# SAM9X60 device description
Architecture: ARM926EJS; Family: SAM9; Series: SAM9X
Registers are 32-bit, read-write, no defined reset value unless marked. A register's access mark holds for its fields unless they carry their own. Offsets are from the block's base; [hi:lo] are bit positions.

## SDRAMC — SDRAM Controller
Instances: SDRAMC 0xFFFFEC00
0x00 SDRAMC_MR — Mode Register
  [2:0] MODE — SDRAMC Command Mode
    0=NORMAL (Normal mode. Any access to the SDRAM is decoded normally. To activate this mode, the command must be followed by a write to the SDRAM.); 1=NOP (The SDRAMC issues a NOP command when the SDRAM device is accessed regardless of the cycle. To activate this mode, the command must be followed by a write to the SDRAM.); 2=ALLBANKS_PRECHARGE (The SDRAMC issues an "All Banks Precharge" command when the SDRAM device is accessed regardless of the cycle. To activate this mode, the command must be followed by a write to the SDRAM.); 3=LOAD_MODEREG (The SDRAMC issues a "Load Mode Register" command when the SDRAM device is accessed regardless of the cycle. To activate this mode, the command must be followed by a write to the SDRAM.); 4=AUTO_REFRESH (The SDRAMC issues an "Autorefresh" Command when the SDRAM device is accessed regardless of the cycle. Previously, an "All Banks Precharge" command must be issued. To activate this mode, the command must be followed by a write to the SDRAM.); 5=EXT_LOAD_MODEREG (The SDRAMC issues an "Extended Load Mode Register" command when the SDRAM device is accessed regardless of the cycle. To activate this mode, the "Extended Load Mode Register" command must be followed by a write to the SDRAM. The write in the SDRAM must be done in the appropriate bank; most low-power SDRAM devices use the bank 1.); 6=DEEP_POWERDOWN (Deep Powerdown mode. Enters Deep Powerdown mode.)
0x04 SDRAMC_TR — Refresh Timer Register
  [11:0] COUNT — SDRAMC Refresh Timer Count
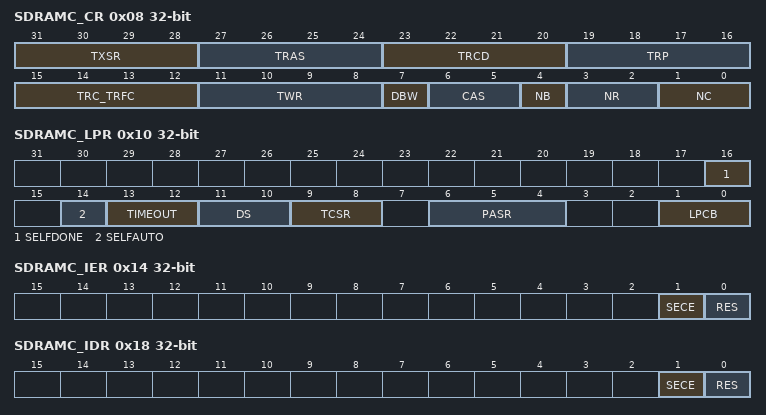
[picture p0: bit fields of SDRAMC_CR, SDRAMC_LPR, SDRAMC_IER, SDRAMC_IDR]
0x08 SDRAMC_CR — Configuration Register
  [31:28] TXSR — Exit Self-Refresh to Active Delay
  [27:24] TRAS — Active to Precharge Delay
  [23:20] TRCD — Row to Column Delay
  [19:16] TRP — Row Precharge Delay
  [15:12] TRC_TRFC — Row Cycle Delay and Row Refresh Cycle
  [11:8] TWR — Write Recovery Delay
  [7] DBW — Data Bus Width
  [6:5] CAS — CAS Latency
    2=LATENCY2 (2-cycle latency); 3=LATENCY3 (3-cycle latency)
  [4] NB — Number of Banks
    0=BANK2 (2 banks); 1=BANK4 (4 banks)
  [3:2] NR — Number of Row Bits
    0=ROW11 (11 bits to define the row number, up to 2048 rows); 1=ROW12 (12 bits to define the row number, up to 4096 rows); 2=ROW13 (13 bits to define the row number, up to 8192 rows)
  [1:0] NC — Number of Column Bits
    0=COL8 (8 bits to define the column number, up to 256 columns); 1=COL9 (9 bits to define the column number, up to 512 columns); 2=COL10 (10 bits to define the column number, up to 1024 columns); 3=COL11 (11 bits to define the column number, up to 2048 columns)
0x0C SDRAMC_HSR — High-Speed Register
  [0] DA — Decode Cycle Enable
0x10 SDRAMC_LPR — Low-Power Register
  [16] SELFDONE — Self-refresh Done (read-only)
  [14] SELFAUTO — Self-refresh Exit Autorefresh
  [13:12] TIMEOUT — Time to Define When Low-power Mode Is Enabled
    0=LP_LAST_XFER (The SDRAMC activates the SDRAM Low-power mode immediately after the end of the last transfer.); 1=LP_LAST_XFER_64 (The SDRAMC activates the SDRAM Low-power mode 64 clock cycles after the end of the last transfer.); 2=LP_LAST_XFER_128 (The SDRAMC activates the SDRAM Low-power mode 128 clock cycles after the end of the last transfer.)
  [11:10] DS — Drive Strength (only for low-power SDRAM)
  [9:8] TCSR — Temperature Compensated Self-Refresh (only for low-power SDRAM)
  [6:4] PASR — Partial Array Self-refresh (only for low-power SDRAM)
  [1:0] LPCB — Low-power Configuration Bits
    0=DISABLED (The low-power feature is inhibited: no Powerdown, Self-refresh or Deep Powerdown command is issued to the SDRAM device.); 1=SELF_REFRESH (The SDRAMC issues a Self-refresh command to the SDRAM device, the SDCK clock is deactivated and the SDCKE signal is set low. The SDRAM device leaves the Self-refresh mode when accessed and enters it after the access.); 2=POWER_DOWN (The SDRAMC issues a Powerdown Command to the SDRAM device after each access, the SDCKE signal is set to low. The SDRAM device leaves the Powerdown mode when accessed and enters it after the access.); 3=DEEP_POWER_DOWN (The SDRAMC issues a Deep Powerdown command to the SDRAM device. This mode is unique to low-power SDRAM.)
0x14 SDRAMC_IER wo — Interrupt Enable Register
  [1] SECE — Security and/or Safety Event Interrupt Enable
  [0] RES — Refresh Error Interrupt Enable
0x18 SDRAMC_IDR wo — Interrupt Disable Register
  [1] SECE — Security and/or Safety Event Interrupt Disable
  [0] RES — Refresh Error Interrupt Disable
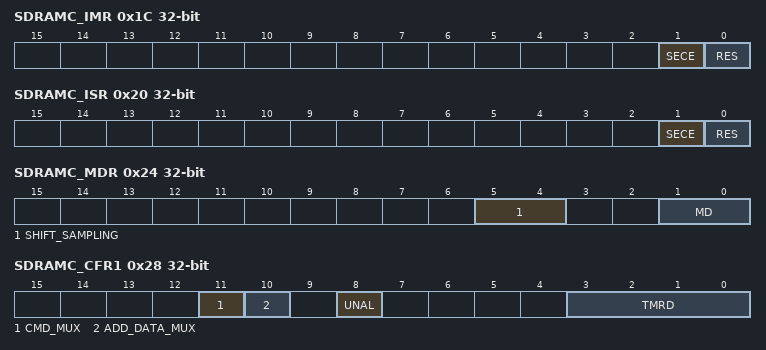
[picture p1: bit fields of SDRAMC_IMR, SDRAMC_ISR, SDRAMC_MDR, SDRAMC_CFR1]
0x1C SDRAMC_IMR ro — Interrupt Mask Register
  [1] SECE — Security and/or Safety Event Interrupt Mask
  [0] RES — Refresh Error Interrupt Mask
0x20 SDRAMC_ISR ro — Interrupt Status Register
  [1] SECE — Security and/or Safety Event (cleared on read)
  [0] RES — Refresh Error Status (cleared on read)
0x24 SDRAMC_MDR — Memory Device Register
  [5:4] SHIFT_SAMPLING — Shift Sampling Point of Data
    1=SHIFT_ONE_CYCLE (Sampling point is shifted by one cycle.); 2=SHIFT_TWO_CYCLES (Sampling point is shifted by two cycles.); 3=SHIFT_THREE_CYCLES (Sampling point is shifted by three cycles.)
  [1:0] MD — Memory Device Type
    0=SDRAM; 1=LPSDRAM (Low-power SDRAM)
0x28 SDRAMC_CFR1 — Configuration Register 1
  [11] CMD_MUX — Commands are Multiplexed with Address and Data
    0=UNSUPPORTED (Commands are not multiplexed with address and data.); 1=SUPPORTED (Commands are multiplexed with address and data.)
  [10] ADD_DATA_MUX — Multiplexed Address and Data
    0=UNSUPPORTED (Data and address are not multiplexed); 1=SUPPORTED (Data and address are multiplexed)
  [8] UNAL — This bit must be always written to 1
  [3:0] TMRD — Load Mode Register Command to Active or Refresh Command
0x2C SDRAMC_OCMS — OCMS Register
  [0] SDR_SE — SDRAM Memory Controller Scrambling Enable
0x30 SDRAMC_OCMS_KEY1 wo — OCMS KEY1 Register
  [31:0] KEY1 — Off-chip Memory Scrambling (OCMS) Key Part 1
0x34 SDRAMC_OCMS_KEY2 wo — OCMS KEY2 Register
  [31:0] KEY2 — Off-chip Memory Scrambling (OCMS) Key Part 2
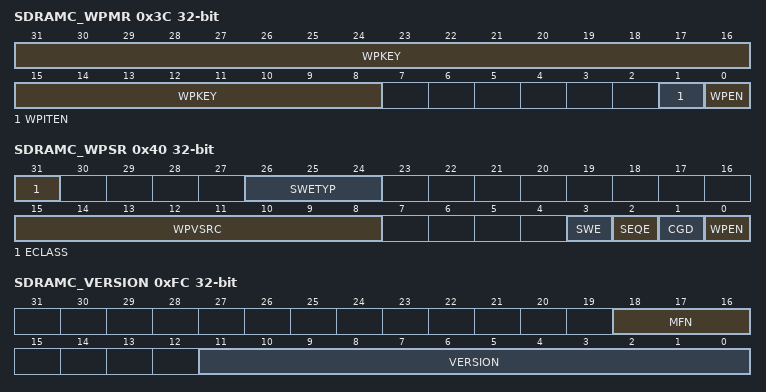
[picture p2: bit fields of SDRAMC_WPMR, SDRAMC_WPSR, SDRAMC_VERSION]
0x3C SDRAMC_WPMR — Write Protection Mode Register
  [31:8] WPKEY — Write Protection Key
    0x534452=PASSWD (Writing any other value in this field aborts the write operation of the WPEN bit. Always reads as 0.)
  [1] WPITEN — Write Protection Interrupt Enable
  [0] WPEN — Write Protection Enable
0x40 SDRAMC_WPSR ro — Write Protection Status Register
  [31] ECLASS — Software Error Class (cleared on read)
    0=WARNING (An abnormal access is performed but it does not affect system functionality.); 1=ERROR (An access is performed into some registers after memory device initialization sequence.)
  [26:24] SWETYP — Software Error Type (cleared on read)
    0=READ_WO (A write-only register has been read (Warning).); 1=WRITE_RO (A write access has been performed on a read-only register (Warning).); 2=UNDEF_RW (Access to an undefined address (Warning).); 3=W_AFTER_INIT (Write access performed into some configuration registers after memory device initialization, i.e. if SDRAMC_TR.COUNT > 0 (Error).)
  [15:8] WPVSRC — Write Protection Violation Source
  [3] SWE — Software Control Error (cleared on read)
  [2] SEQE — Internal Sequencer Error (cleared on read)
  [1] CGD — Clock Glitch Detected (cleared on read)
  [0] WPEN — Write Protection Violation Status (cleared on read)
0xFC SDRAMC_VERSION ro — Version Register
  [18:16] MFN — Metal Fix Number
  [11:0] VERSION — Version of the Hardware Module
